# STM32H573 register map
File version: 1.8
CPU: CM33 r0p0, little endian, MPU, FPU, 4 interrupt priority bits
Registers are 32-bit, read-write, reset 0x0 unless marked. A register's access mark holds for its fields unless they carry their own. Offsets are from the block's base; [hi:lo] are bit positions; 'fields as' and 'values as' point back to an identical list.

## RCC (part 1 of 2) — Reset and clock controller
Base 0x44020C00
Same registers: SEC_RCC 0x54020C00
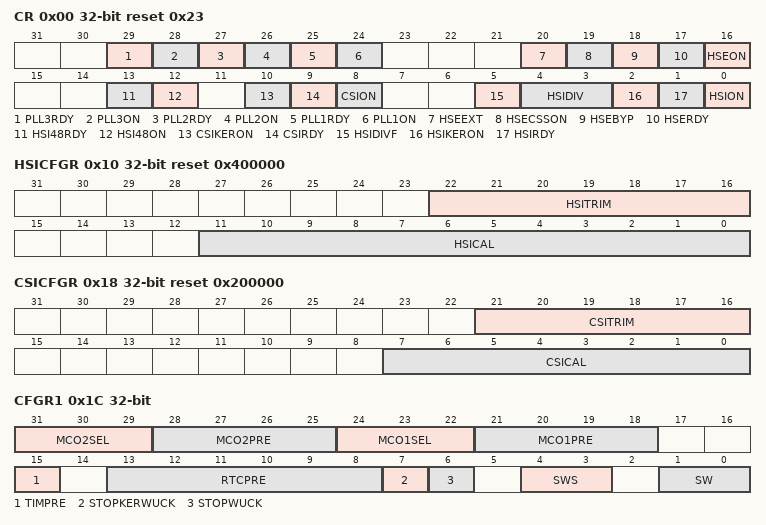
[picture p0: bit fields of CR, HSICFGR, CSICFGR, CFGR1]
0x00 CR access per field reset 0x23 — RCC clock control register
  [29] PLL3RDY ro — PLL3 clock ready flag Set by hardware to indicate that the PLL3 is locked.
    0=NotReady (Clock not ready); 1=Ready (Clock ready)
  [28] PLL3ON rw — PLL3 enable Set and cleared by software to enable PLL3. Cleared by hardware when entering Stop or Standby mode.
    0=Off (Clock Off); 1=On (Clock On)
  [27] PLL2RDY ro — PLL2 clock ready flag Set by hardware to indicate that the PLL is locked.
    0=NotReady (Clock not ready); 1=Ready (Clock ready)
  [26] PLL2ON rw — PLL2 enable Set and cleared by software to enable PLL2. Cleared by hardware when entering Stop or Standby mode.
    0=Off (Clock Off); 1=On (Clock On)
  [25] PLL1RDY ro — PLL1 clock ready flag Set by hardware to indicate that the PLL1 is locked.
    0=NotReady (Clock not ready); 1=Ready (Clock ready)
  [24] PLL1ON rw — PLL1 enable Set and cleared by software to enable PLL1. Cleared by hardware when entering Stop or Standby mode. Note that the hardware prevents writing this bit to 0, if the PLL1 output is used as the system clock.
    0=Off (Clock Off); 1=On (Clock On)
  [20] HSEEXT rw — external high speed clock type in Bypass mode Set and reset by software to select the external clock type (analog or digital). The external clock must be enabled with the HSEON bit to be used by the device. The HSEEXT bit can be written only if the HSE oscillator is disabled.
    0=Analog (HSE in analog mode); 1=Digital (HSE in digital mode)
  [19] HSECSSON rw — HSE clock security system enable Set by software to enable clock security system on HSE. This bit is 'set only' (disabled by a system reset or when the system enters in Standby mode). When HSECSSON is set, the clock detector is enabled by hardware when the HSE is ready and disabled by hardware if an oscillator failure is detected.
    0=Off (Clock Off); 1=On (Clock On)
  [18] HSEBYP rw — HSE clock bypass Set and cleared by software to bypass the oscillator with an external clock. The external clock must be enabled with the HSEON bit to be used by the device. The HSEBYP bit can be written only if the HSE oscillator is disabled.
    0=NotBypassed (HSE crystal oscillator not bypassed); 1=Bypassed (HSE crystal oscillator bypassed with external clock)
  [17] HSERDY ro — HSE clock ready flag Set by hardware to indicate that the HSE oscillator is stable.
    0=NotReady (Clock not ready); 1=Ready (Clock ready)
  [16] HSEON rw — HSE clock enable Set and cleared by software. Cleared by hardware to stop the HSE when entering Stop or Standby mode. This bit cannot be cleared if the HSE is used directly (via SW mux) as system clock, or if the HSE is selected as reference clock for PLL1 with PLL1 enabled (PLL1ON bit set to 1).
    0=Off (Clock Off); 1=On (Clock On)
  [13] HSI48RDY ro — HSI48 clock ready flag Set by hardware to indicate that the HSI48 oscillator is stable.
    0=NotReady (Clock not ready); 1=Ready (Clock ready)
  [12] HSI48ON rw — HSI48 clock enable Set by software and cleared by software or by the hardware when the system enters to Stop or Standby mode.
    0=Off (Clock Off); 1=On (Clock On)
  [10] CSIKERON rw — CSI clock enable in Stop mode Set and reset by software to force the CSI to ON, even in Stop mode, in order to be quickly available as kernel clock for some peripherals. This bit has no effect on the value of CSION.
    0=Off (Clock Off); 1=On (Clock On)
  [9] CSIRDY ro — CSI clock ready flag Set by hardware to indicate that the CSI oscillator is stable. This bit is activated only if the RC is enabled by CSION (it is not activated if the CSI is enabled by CSIKERON or by a peripheral request).
    0=NotReady (Clock not ready); 1=Ready (Clock ready)
  [8] CSION rw — CSI clock enable Set and reset by software to enable/disable CSI clock for system and/or peripheral. Set by hardware to force the CSI to ON when the system leaves Stop mode, if STOPWUCK = 1 or STOPKERWUCK = 1. This bit cannot be cleared if the CSI is used directly (via SW mux) as system clock, or if the CSI is selected as reference clock for PLL1 with PLL1 enabled (PLL1ON bit set to 1).
    0=Off (Clock Off); 1=On (Clock On)
  [5] HSIDIVF ro — HSI divider flag Set and reset by hardware. As a write operation to HSIDIV has not an immediate effect on the frequency, this flag indicates the current status of the HSI divider. HSIDIVF goes immediately to 0 when HSIDIV value is changed, and is set back to 1 when the output frequency matches the value programmed into HSIDIV.
    0=NotPropagated (New HSIDIV ratio has not yet propagated to hsi_ck); 1=Propagated (HSIDIV ratio has propagated to hsi_ck)
  [4:3] HSIDIV rw — HSI clock divider Set and reset by software. These bits allow selecting a division ratio in order to configure the wanted HSI clock frequency. The HSIDIV cannot be changed if the HSI is selected as reference clock for at least one enabled PLL (PLLxON bit set to 1). In that case, the new HSIDIV value is ignored.
    0=Div1 (No division); 1=Div2 (Division by 2); 2=Div4 (Division by 4); 3=Div8 (Division by 8)
  [2] HSIKERON rw — HSI clock enable in Stop mode Set and reset by software to force the HSI to ON, even in Stop mode, in order to be quickly available as kernel clock for peripherals. This bit has no effect on the value of HSION.
    0=Off (Clock Off); 1=On (Clock On)
  [1] HSIRDY ro — HSI clock ready flag Set by hardware to indicate that the HSI oscillator is stable.
    0=NotReady (Clock not ready); 1=Ready (Clock ready)
  [0] HSION rw — HSI clock enable Set and cleared by software. Set by hardware to force the HSI to ON when the product leaves Stop mode, if STOPWUCK = 1 or STOPKERWUCK = 1. Set by hardware to force the HSI to ON when the product leaves Standby mode or in case of a failure of the HSE which is used as the system clock source. This bit cannot be cleared if the HSI is used directly (via SW mux) as system clock, or if the HSI is selected as reference clock for PLL1 with PLL1 enabled (PLL1ON bit set to 1).
    0=Off (Clock Off); 1=On (Clock On)
0x10 HSICFGR access per field reset 0x400000 (reset mask 0xFFFFF000) — RCC HSI calibration register
  [22:16] HSITRIM rw — HSI clock trimming Set by software to adjust calibration. HSITRIM field is added to the engineering option bytes loaded during reset phase (FLASH_HSI_OPT) in order to form the calibration trimming value. HSICAL = HSITRIM + FLASH_HSI_OPT. After a change of HSITRIM it takes one system clock cycle before the new HSITRIM value is updated Note: The reset value of the field is 0x40.
  [11:0] HSICAL ro — HSI clock calibration Set by hardware by option byte loading during system reset nreset. Adjusted by software through trimming bits HSITRIM. This field represents the sum of engineering option byte calibration value and HSITRIM bits value.
0x14 CRRCR ro (reset mask 0xFFFFF000) — RCC clock recovery RC register
  [9:0] HSI48CAL — Internal RC 48 MHz clock calibration Set by hardware by option-byte loading during system reset NRESET. Read-only.
0x18 CSICFGR reset 0x200000 (reset mask 0xFFFFF000) — RCC CSI calibration register
  [21:16] CSITRIM — CSI clock trimming Set by software to adjust calibration. CSITRIM field is added to the engineering option bytes loaded during reset phase (FLASH_CSI_OPT) in order to form the calibration trimming value. CSICAL = CSITRIM + FLASH_CSI_OPT. Note: The reset value of the field is 0x20.
  [7:0] CSICAL — CSI clock calibration Set by hardware by option byte loading during system reset NRESET. Adjusted by software through trimming bits CSITRIM. This field represents the sum of engineering option byte calibration value and CSITRIM bits value.
0x1C CFGR1 access per field — RCC clock configuration register
  [31:29] MCO2SEL rw — microcontroller clock output 2 Set and cleared by software. Clock source selection may generate glitches on MCO2. It is highly recommended to configure these bits only after reset, before enabling the external oscillators and the PLLs. others: reserved
    0=SYSCLK (System clock selected (sys_ck)); 1=PLL2_P (PLL2 oscillator clock selected (pll2_p_ck)); 2=HSE (HSE clock selected (hse_ck)); 3=PLL1_P (PLL1 clock selected (pll1_p_ck)); 4=CSI (CSI clock selected (csi_ck)); 5=LSI (LSI clock selected (lsi_ck))
  [28:25] MCO2PRE rw — MCO2 prescaler Set and cleared by software to configure the prescaler of the MCO2. Modification of this prescaler may generate glitches on MCO2. It is highly recommended to change this prescaler only after reset, before enabling the external oscillators and the PLLs. ...
  [24:22] MCO1SEL rw — Microcontroller clock output 1 Set and cleared by software. Clock source selection may generate glitches on MCO1. It is highly recommended to configure these bits only after reset, before enabling the external oscillators and the PLLs. others: reserved
    0=HSI (HSI clock selected (hsi_ck)); 1=LSE (LSE clock selected (lse_ck)); 2=HSE (HSE clock selected (hse_ck)); 3=PLL1_Q (PLL1 clock selected (pll1_q_ck)); 4=HSI48 (HSI48 clock selected (hsi48_ck))
  [21:18] MCO1PRE rw — MCO1 prescaler Set and cleared by software to configure the prescaler of the MCO1. Modification of this prescaler may generate glitches on MCO1. It is highly recommended to change this prescaler only after reset, before enabling the external oscillators and the PLLs. ...
  [15] TIMPRE rw — timers clocks prescaler selection This bit is set and reset by software to control the clock frequency of all the timers connected to APB1 and APB2 domains.
    0=DefaultX2 (Timer kernel clock equal to 2x pclk by default); 1=DefaultX4 (Timer kernel clock equal to 4x pclk by default)
  [13:8] RTCPRE rw — HSE division factor for RTC clock Set and cleared by software to divide the HSE to generate a clock for RTC. Caution: The software must set these bits correctly to ensure that the clock supplied to the RTC is lower than 1 MHz. These bits must be configured if needed before selecting the RTC clock source. ...
  [7] STOPKERWUCK rw — kernel clock selection after a wakeup from system Stop Set and reset by software to select the kernel wakeup clock from system Stop.
    0=HSI (HSI selected as wake up clock from system Stop); 1=CSI (CSI selected as wake up clock from system Stop)
  [6] STOPWUCK rw — system clock selection after a wakeup from system Stop Set and reset by software to select the system wakeup clock from system Stop. The selected clock is also used as emergency clock for the clock security system (CSS) on HSE. 0: HSI selected as wakeup clock from system Stop (default after reset) STOPWUCK must not be modified when CSS is enabled (by HSECSSON bit) and the system clock is HSE (SWS = 10) or a switch on HSE is requested (SW =10).
    values as STOPKERWUCK
  [4:3] SWS ro — system clock switch status Set and reset by hardware to indicate which clock source is used as system clock. 000: HSI used as system clock (hsi_ck) (default after reset). others: reserved
    0=HSI (HSI oscillator used as system clock); 1=CSI (CSI oscillator used as system clock); 2=HSE (HSE oscillator used as system clock); 3=PLL1 (PLL1 used as system clock)
  [1:0] SW rw — system clock and trace clock switch Set and reset by software to select system clock and trace clock sources (sys_ck). Set by hardware in order to: - force the selection of the HSI or CSI (depending on STOPWUCK selection) when leaving a system Stop mode - force the selection of the HSI in case of failure of the HSE when used directly or indirectly as system clock others: reserved
    0=HSI (HSI selected as system clock); 1=CSI (CSI selected as system clock); 2=HSE (HSE selected as system clock); 3=PLL1 (PLL1 selected as system clock)
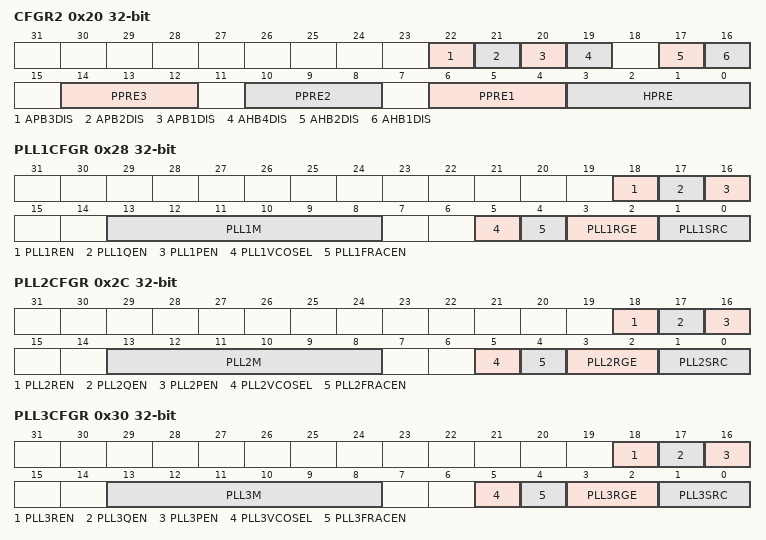
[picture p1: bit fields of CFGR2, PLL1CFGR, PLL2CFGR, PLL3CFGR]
0x20 CFGR2 — RCC CPU domain clock configuration register 2
  [22] APB3DIS — APB3 clock disable value.Set and cleared by software This bit can be set in order to further reduce power consumption, when none of the APB3 peripherals are used and when their clocks are disabled in RCC_APB3ENR. When this bit is set, all the APB3 peripherals clocks are off. control bits
    0=Enabled (The selected clock is enabled); 1=Disabled (The selected clock is disabled)
  [21] APB2DIS — APB2 clock disable value This bit can be set in order to further reduce power consumption, when none of the APB2 peripherals are used and when their clocks are disabled in RCC_APB2ENR. When this bit is set, all the APB2 peripherals clocks are off. control bits
    values as APB3DIS
  [20] APB1DIS — APB1 clock disable value This bit can be set in order to further reduce power consumption, when none of the APB1 peripherals (except IWDG) are used and when their clocks are disabled in RCC_APB1ENR. When this bit is set, all the APB1 peripherals clocks are off, except for IWDG. control bits
    values as APB3DIS
  [19] AHB4DIS — AHB4 clock disable This bit can be set in order to further reduce power consumption, when none of the AHB4 peripherals from RCC_AHB4ENR are used and when their clocks are disabled in RCC_AHB4ENR. When this bit is set, all the AHB4 peripherals clocks from RCC_AHB4ENR are off. enable control bits
    values as APB3DIS
  [17] AHB2DIS — AHB2 clock disable This bit can be set in order to further reduce power consumption, when none of the AHB2 peripherals from RCC_AHB2ENR are used and when their clocks are disabled in RCC_AHB2ENR. When this bit is set, all the AHB2 peripherals clocks from RCC_AHB2ENR are off. enable control bits
    values as APB3DIS
  [16] AHB1DIS — AHB1 clock disable This bit can be set in order to further reduce power consumption, when none of the AHB1 peripherals from RCC_AHB1ENR are used and when their clocks are disabled in RCC_AHB1ENR. When this bit is set, all the AHB1 peripherals clocks from RCC_AHB1ENR are off. enable control bits
    values as APB3DIS
  [14:12] PPRE3 — APB low-speed prescaler (APB3) Set and reset by software to control APB low-speed clocks division factor. The clocks are divided with the new prescaler factor from 1 to 16 APB cycles after PPRE3 write. 0xx: rcc_pclk3 = rcc_hclk1
    4=Div2 (HCLK divided by 2); 5=Div4 (HCLK divided by 4); 6=Div8 (HCLK divided by 8); 7=Div16 (HCLK divided by 16); other=Div1 (HCLK not divided)
  [10:8] PPRE2 — APB high-speed prescaler (APB2) Set and reset by software to control APB high-speed clocks division factor. The clocks are divided with the new prescaler factor from 1 to 16 APB cycles after PPRE2 write. 0xx: rcc_pclk2 = rcc_hclk1
    values as PPRE3
  [6:4] PPRE1 — APB low-speed prescaler (APB1) Set and reset by software to control the division factor of rcc_pclk1. The clock is divided by the new prescaler factor from 1 to 16 cycles of rcc_hclk after PPRE write. 0xx: rcc_pclk1 = rcc_hclk1 (default after reset)
    values as PPRE3
  [3:0] HPRE — AHB prescaler Set and reset by software to control the division factor of rcc_hclk. Changing this division ratio has an impact on the frequency of all bus matrix clocks 0xxx: rcc_hclk = sys_ck (default after reset)
    8=Div2 (SYSCLK divided by 2); 9=Div4 (SYSCLK divided by 4); 10=Div8 (SYSCLK divided by 8); 11=Div16 (SYSCLK divided by 16); 12=Div64 (SYSCLK divided by 64); 13=Div128 (SYSCLK divided by 128); 14=Div256 (SYSCLK divided by 256); 15=Div512 (SYSCLK divided by 512); other=Div1 (SYSCLK not divided)
0x28 PLL1CFGR — RCC PLL clock source selection register
  [18] PLL1REN — PLL1 DIVR divider output enable Set and reset by software to enable the pll1_r_ck output of the PLL1. To save power, DIVR1EN and DIVR1 bits must be set to 0 when the pll1_r_ck is not used. This bit can be written only when the PLL1 is disabled (PLL1ON = 0 and PLL1RDY = 0).
    0=Disabled (Clock output is disabled); 1=Enabled (Clock output is enabled)
  [17] PLL1QEN — PLL1 DIVQ divider output enable Set and reset by software to enable the pll1_q_ck output of the PLL1. In order to save power, when the pll1_q_ck output of the PLL1 is not used, the pll1_q_ck must be disabled. This bit can be written only when the PLL1 is disabled (PLL1ON = 0 and PLL1RDY = 0).
    values as PLL1REN
  [16] PLL1PEN — PLL1 DIVP divider output enable Set and reset by software to enable the pll1_p_ck output of the PLL1. This bit can be written only when the PLL1 is disabled (PLL1ON = 0 and PLL1RDY = 0). In order to save power, when the pll1_p_ck output of the PLL1 is not used, the pll1_p_ck must be disabled.
    values as PLL1REN
  [13:8] PLL1M — prescaler for PLL1 Set and cleared by software to configure the prescaler of the PLL1. The hardware does not allow any modification of this prescaler when PLL1 is enabled (PLL1ON = 1 or PLL1RDY = 1). In order to save power when PLL1 is not used, the value of DIVM1 must be set to 0. ... ...
  [5] PLL1VCOSEL — PLL1 VCO selection Set and reset by software to select the proper VCO frequency range used for PLL1. This bit must be written before enabling the PLL1.
    0=WideVCO (VCO frequency range 192 to 836 MHz); 1=MediumVCO (VCO frequency range 150 to 420 MHz)
  [4] PLL1FRACEN — PLL1 fractional latch enable Set and reset by software to latch the content of FRACN1 into the sigma-delta modulator. In order to latch the FRACN1 value into the sigma-delta modulator, PLL1FRACEN must be set to 0, then set to 1. The transition 0 to 1 transfers the content of FRACN1 into the modulator.
    0=Reset latch to transfer FRACN to the Sigma-Delta modulator; 1=Set (Set latch to transfer FRACN to the Sigma-Delta modulator)
  [3:2] PLL1RGE — PLL1 input frequency range Set and reset by software to select the proper reference frequency range used for PLL1. This bit must be written before enabling the PLL1.
    0=Range1 (Frequency is between 1 and 2 MHz); 1=Range2 (Frequency is between 2 and 4 MHz); 2=Range4 (Frequency is between 4 and 8 MHz); 3=Range8 (Frequency is between 8 and 16 MHz)
  [1:0] PLL1SRC — DIVMx and PLLs clock source selection Set and reset by software to select the PLL clock source. These bits can be written only when all PLLs are disabled. In order to save power, when no PLL is used, the value of PLL1SRC must be set to '00'. 00: no clock send to DIVMx divider and PLLs (default after reset).
    0=None (No clock sent to DIVMx dividers and PLLs); 1=HSI (HSI selected as PLL clock); 2=CSI (CSI selected as PLL clock); 3=HSE (HSE selected as PLL clock)
0x2C PLL2CFGR — RCC PLL clock source selection register
  [18] PLL2REN — PLL2 DIVR divider output enable Set and reset by software to enable the pll2_r_ck output of the PLL2. To save power, DIVR2EN and DIVR2 bits must be set to 0 when the pll2_r_ck is not used.
    values as PLL1CFGR.PLL1REN
  [17] PLL2QEN — PLL2 DIVQ divider output enable Set and reset by software to enable the pll2_q_ck output of the PLL2. To save power, when the pll2_q_ck output of the PLL2 is not used, the pll2_q_ck must be disabled.
    values as PLL1CFGR.PLL1REN
  [16] PLL2PEN — PLL2 DIVP divider output enable Set and reset by software to enable the pll2_p_ck output of the PLL2. To save power, when the pll2_p_ck output of the PLL2 is not used, the pll2_p_ck must be disabled.
    values as PLL1CFGR.PLL1REN
  [13:8] PLL2M — prescaler for PLL2 Set and cleared by software to configure the prescaler of the PLL2. The hardware does not allow any modification of this prescaler when PLL2 is enabled (PLL2ON = 1 or PLL2RDY = 1). In order to save power when PLL2 is not used, the value of DIVM2 must be set to 0. ... ...
  [5] PLL2VCOSEL — PLL2 VCO selection Set and reset by software to select the proper VCO frequency range used for PLL2. This bit must be written before enabling the PLL2.
    values as PLL1CFGR.PLL1VCOSEL
  [4] PLL2FRACEN — PLL2 fractional latch enable Set and reset by software to enable the pll2_p_ck output of the PLL2. To save power, when the pll2_p_ck output of the PLL2 is not used, the pll2_p_ck must be disabled.
    values as PLL1CFGR.PLL1FRACEN
  [3:2] PLL2RGE — PLL2 input frequency range Set and reset by software to select the proper reference frequency range used for PLL2. These bits must be written before enabling the PLL2.
    values as PLL1CFGR.PLL1RGE
  [1:0] PLL2SRC — DIVMx and PLLs clock source selection Set and reset by software to select the PLL clock source. These bits can be written only when all PLLs are disabled. In order to save power, when no PLL is used, the value of PLL2SRC must be set to '00'.
    values as PLL1CFGR.PLL1SRC
0x30 PLL3CFGR — RCC PLL clock source selection register
  [18] PLL3REN — PLL3 DIVR divider output enable Set and reset by software to enable the pll3_r_ck output of the PLL3. To save power, DIVR2EN and DIVR2 bits must be set to 0 when the pll3_r_ck is not used.
    values as PLL1CFGR.PLL1REN
  [17] PLL3QEN — PLL3 DIVQ divider output enable Set and reset by software to enable the pll3_q_ck output of the PLL3. To save power, when the pll3_q_ck output of the PLL3 is not used, the pll3_q_ck must be disabled.
    values as PLL1CFGR.PLL1REN
  [16] PLL3PEN — PLL3 DIVP divider output enable Set and reset by software to enable the pll3_p_ck output of the PLL3. To save power, when the pll3_p_ck output of the PLL3 is not used, the pll3_p_ck must be disabled.
    values as PLL1CFGR.PLL1REN
  [13:8] PLL3M — prescaler for PLL3 Set and cleared by software to configure the prescaler of the PLL3. The hardware does not allow any modification of this prescaler when PLL3 is enabled (PLL3ON = 1 or PLL3RDY = 1). In order to save power when PLL3 is not used, the value of DIVM2 must be set to 0. ... ...
  [5] PLL3VCOSEL — PLL3 VCO selection Set and reset by software to select the proper VCO frequency range used for PLL3. This bit must be written before enabling the PLL3.
    values as PLL1CFGR.PLL1VCOSEL
  [4] PLL3FRACEN — PLL3 fractional latch enable Set and reset by software to latch the content of FRACN3 into the sigma-delta modulator. In order to latch the FRACN3 value into the sigma-delta modulator, PLL3FRACEN must be set to 0, then set to 1. The transition 0 to 1 transfers the content of FRACN3 into the modulator.
    values as PLL1CFGR.PLL1FRACEN
  [3:2] PLL3RGE — PLL3 input frequency range Set and reset by software to select the proper reference frequency range used for PLL3. This bit must be written before enabling the PLL3.
    values as PLL1CFGR.PLL1RGE
  [1:0] PLL3SRC — DIVMx and PLLs clock source selection Set and reset by software to select the PLL clock source. These bits can be written only when all PLLs are disabled. In order to save power, when no PLL is used, the value of PLL3SRC must be set to '00'.
    values as PLL1CFGR.PLL1SRC
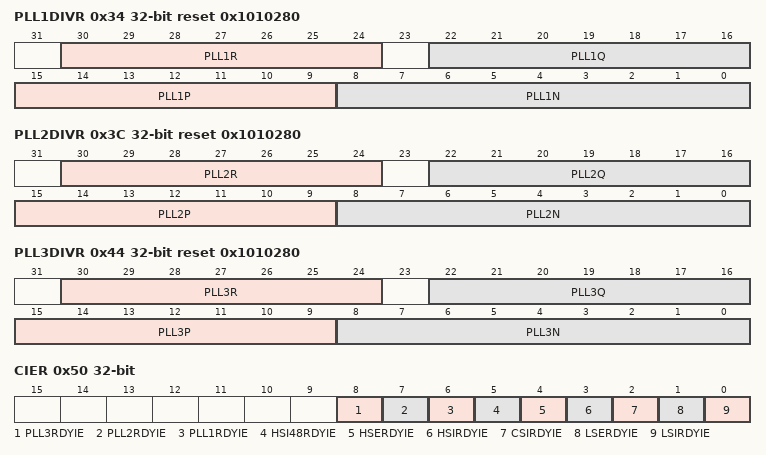
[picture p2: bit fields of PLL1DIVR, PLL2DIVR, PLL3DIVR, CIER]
0x34 PLL1DIVR reset 0x1010280 — RCC PLL1 dividers register
  [30:24] PLL1R — PLL1 DIVR division factor Set and reset by software to control the frequency of the pll1_r_ck clock. These bits can be written only when the PLL1 is disabled (PLL1ON = 0 and PLL1RDY = 0). ...
  [22:16] PLL1Q — PLL1 DIVQ division factor Set and reset by software to control the frequency of the pll1_q_ck clock. These bits can be written only when the PLL1 is disabled (PLL1ON = 0 and PLL1RDY = 0). ...
  [15:9] PLL1P — PLL1 DIVP division factor Set and reset by software to control the frequency of the pll1_p_ck clock. These bits can be written only when the PLL1 is disabled (PLL1ON = 0 and PLL1RDY = 0). Note that odd division factors are not allowed. ...
  [8:0] PLL1N range 3..511 — Multiplication factor for PLL1VCO Set and reset by software to control the multiplication factor of the VCO. These bits can be written only when the PLL is disabled (PLL1ON = 0 and PLL1RDY = 0). ... ... Others: reserved
0x38 PLL1FRACR — RCC PLL1 fractional divider register
  [15:3] PLL1FRACN — fractional part of the multiplication factor for PLL1 VCO Set and reset by software to control the fractional part of the multiplication factor of the VCO. These bits can be written at any time, allowing dynamic fine-tuning of the PLL1 VCO. The software must set correctly these bits to insure that the VCO output frequency is between its valid frequency range, that is: * 128 to 560 MHz if PLL1VCOSEL = 0 * 150 to 420 MHz if PLL1VCOSEL = 1 VCO output frequency = Fref1_ck x (PLL1N + (PLL1FRACN / 213)), with * PLL1N between 8 and 420 * PLL1FRACN can be between 0 and 213- 1 * The input frequency Fref1_ck must be between 1 and 16 MHz. To change the PLL1FRACN value on-the-fly even if the PLL is enabled, the application must proceed as follows: * Set the bit PLL1FRACEN to 0 * Write the new fractional value into PLL1FRACN * Set the bit PLL1FRACEN to 1
0x3C PLL2DIVR reset 0x1010280 — RCC PLL1 dividers register
  [30:24] PLL2R — PLL2 DIVR division factor Set and reset by software to control the frequency of the pll2_r_ck clock. These bits can be written only when the PLL1 is disabled (PLL2ON = 0 and PLL2RDY = 0). ...
  [22:16] PLL2Q — PLL2 DIVQ division factor Set and reset by software to control the frequency of the pll2_q_ck clock. These bits can be written only when the PLL2 is disabled (PLL2ON = 0 and PLL2RDY = 0). ...
  [15:9] PLL2P — PLL2 DIVP division factor Set and reset by software to control the frequency of the pll2_p_ck clock. These bits can be written only when the PLL2 is disabled (PLL2ON = 0 and PLL2RDY = 0). ...
  [8:0] PLL2N range 3..511 — Multiplication factor for PLL2VCO Set and reset by software to control the multiplication factor of the VCO. These bits can be written only when the PLL is disabled (PLL2ON = 0 and PLL2RDY = 0). ... ... Others: reserved
0x40 PLL2FRACR — RCC PLL2 fractional divider register
  [15:3] PLL2FRACN — fractional part of the multiplication factor for PLL2 VCO Set and reset by software to control the fractional part of the multiplication factor of the VCO. These bits can be written at any time, allowing dynamic fine-tuning of the PLL2 VCO. The software must set correctly these bits to insure that the VCO output frequency is between its valid frequency range, that is: * 128 to 560 MHz if PLL2VCOSEL = 0 * 150 to 420 MHz if PLL2VCOSEL = 1 VCO output frequency = Fref2_ck x (PLL2N + (PLL2FRACN / 213)), with * PLL2N between 8 and 420 * PLL2FRACN can be between 0 and 213- 1 * The input frequency Fref2_ck must be between 1 and 16 MHz. To change the PLL2FRACN value on-the-fly even if the PLL is enabled, the application must proceed as follows: * Set the bit PLL2FRACEN to 0 * Write the new fractional value into PLL2FRACN * Set the bit PLL2FRACEN to 1
0x44 PLL3DIVR reset 0x1010280 — RCC PLL3 dividers register
  [30:24] PLL3R — PLL3 DIVR division factor Set and reset by software to control the frequency of the pll3_r_ck clock. These bits can be written only when the PLL1 is disabled (PLL3ON = 0 and PLL3RDY = 0). ...
  [22:16] PLL3Q — PLL3 DIVQ division factor Set and reset by software to control the frequency of the pll3_q_ck clock. These bits can be written only when the PLL3 is disabled (PLL3ON = 0 and PLL3RDY = 0). ...
  [15:9] PLL3P — PLL3 DIVP division factor Set and reset by software to control the frequency of the pll3_p_ck clock. These bits can be written only when the PLL3 is disabled (PLL3ON = 0 and PLL3RDY = 0). ...
  [8:0] PLL3N range 3..511 — Multiplication factor for PLL3VCO Set and reset by software to control the multiplication factor of the VCO. These bits can be written only when the PLL is disabled (PLL3ON = 0 and PLL3RDY = 0). ... ... Others: reserved
0x48 PLL3FRACR — RCC PLL3 fractional divider register
  [15:3] PLL3FRACN — fractional part of the multiplication factor for PLL3 VCO Set and reset by software to control the fractional part of the multiplication factor of the VCO. These bits can be written at any time, allowing dynamic fine-tuning of the PLL3 VCO. The software must set correctly these bits to insure that the VCO output frequency is between its valid frequency range, that is: * 128 to 560 MHz if PLL3VCOSEL = 0 * 150 to 420 MHz if PLL3VCOSEL = 1 VCO output frequency = Fref3_ck x (PLL3N + (PLL3FRACN / 213)), with * PLL3N between 8 and 420 * PLL3FRACN can be between 0 and 213- 1 * The input frequency Fref3_ck must be between 1 and 16 MHz. To change the PLL3FRACN value on-the-fly even if the PLL is enabled, the application must proceed as follows: * Set the bit PLL3FRACEN to 0 * Write the new fractional value into PLL3FRACN * Set the bit PLL3FRACEN to 1.
0x50 CIER — RCC clock source interrupt enable register
  [all] fields
    0=Disabled (Interrupt disabled); 1=Enabled (Interrupt enabled)
  [8] PLL3RDYIE — PLL3 ready interrupt enable Set and reset by software to enable/disable interrupt caused by PLL3 lock.
  [7] PLL2RDYIE — PLL2 ready interrupt enable Set and reset by software to enable/disable interrupt caused by PLL2 lock.
  [6] PLL1RDYIE — PLL1 ready interrupt enable Set and reset by software to enable/disable interrupt caused by PLL1 lock.
  [5] HSI48RDYIE — HSI48 ready interrupt enable Set and reset by software to enable/disable interrupt caused by the HSI48 oscillator stabilization.
  [4] HSERDYIE — HSE ready interrupt enable Set and reset by software to enable/disable interrupt caused by the HSE oscillator stabilization.
  [3] HSIRDYIE — HSI ready interrupt enable Set and reset by software to enable/disable interrupt caused by the HSI oscillator stabilization.
  [2] CSIRDYIE — CSI ready interrupt enable Set and reset by software to enable/disable interrupt caused by the CSI oscillator stabilization.
  [1] LSERDYIE — LSE ready interrupt enable Set and reset by software to enable/disable interrupt caused by the LSE oscillator stabilization.
  [0] LSIRDYIE — LSI ready interrupt enable Set and reset by software to enable/disable interrupt caused by the LSI oscillator stabilization.
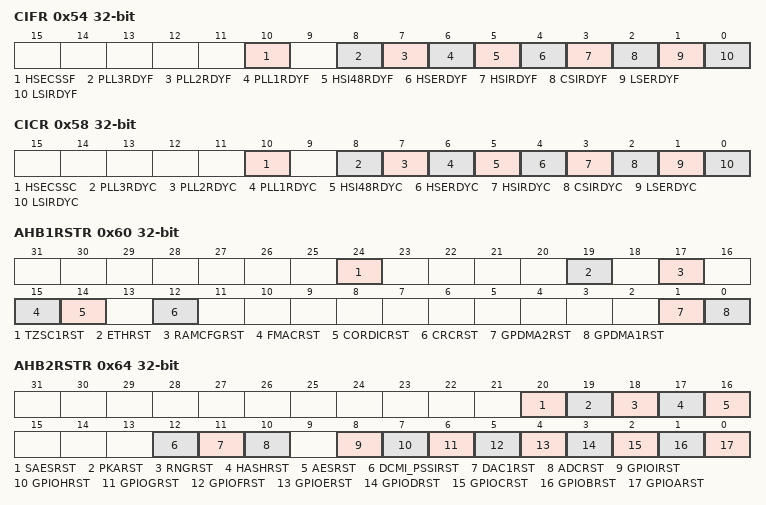
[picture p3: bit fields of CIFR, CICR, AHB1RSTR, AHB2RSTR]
0x54 CIFR ro — RCC clock source interrupt flag register
  [10] HSECSSF — HSE clock security system interrupt flag Reset by software by writing HSECSSC bit. Set by hardware in case of HSE clock failure.
    0=NoInterrupt (No clock security interrupt caused by HSE clock failure); 1=Interrupt (Clock security interrupt caused by HSE clock failure)
  [8] PLL3RDYF — PLL3 ready interrupt flag Reset by software by writing PLL3RDYC bit. Set by hardware when the PLL3 locks and PLL3RDYIE is set.
    0=NotInterrupted (No clock ready interrupt); 1=Interrupted (Clock ready interrupt)
  [7] PLL2RDYF — PLL2 ready interrupt flag Reset by software by writing PLL2RDYC bit. Set by hardware when the PLL2 locks and PLL2RDYIE is set.
    values as PLL3RDYF
  [6] PLL1RDYF — PLL1 ready interrupt flag Reset by software by writing PLL1RDYC bit. Set by hardware when the PLL1 locks and PLL1RDYIE is set.
    values as PLL3RDYF
  [5] HSI48RDYF — HSI48 ready interrupt flag Reset by software by writing HSI48RDYC bit. Set by hardware when the HSI48 clock becomes stable and HSI48RDYIE is set.
    values as PLL3RDYF
  [4] HSERDYF — HSE ready interrupt flag Reset by software by writing HSERDYC bit. Set by hardware when the HSE clock becomes stable and HSERDYIE is set.
    values as PLL3RDYF
  [3] HSIRDYF — HSI ready interrupt flag Reset by software by writing HSIRDYC bit. Set by hardware when the HSI clock becomes stable and HSIRDYIE is set.
    values as PLL3RDYF
  [2] CSIRDYF — CSI ready interrupt flag Reset by software by writing CSIRDYC bit. Set by hardware when the CSI clock becomes stable and CSIRDYIE is set.
    values as PLL3RDYF
  [1] LSERDYF — LSE ready interrupt flag Reset by software by writing LSERDYC bit. Set by hardware when the LSE clock becomes stable and LSERDYIE is set.
    values as PLL3RDYF
  [0] LSIRDYF — LSI ready interrupt flag Reset by software by writing LSIRDYC bit. Set by hardware when the LSI clock becomes stable and LSIRDYIE is set.
    values as PLL3RDYF
0x58 CICR — RCC clock source interrupt clear register
  [all] fields
    1=Clear interrupt flag
  [10] HSECSSC — HSE clock security system interrupt clear Set by software to clear HSECSSF. Reset by hardware when clear done.
  [8] PLL3RDYC — PLL3 ready interrupt clear Set by software to clear PLL3RDYF. Reset by hardware when clear done.
  [7] PLL2RDYC — PLL2 ready interrupt clear Set by software to clear PLL2RDYF. Reset by hardware when clear done.
  [6] PLL1RDYC — PLL1 ready interrupt clear Set by software to clear PLL1RDYF. Reset by hardware when clear done.
  [5] HSI48RDYC — HSI48 ready interrupt clear Set by software to clear HSI48RDYF. Reset by hardware when clear done.
  [4] HSERDYC — HSE ready interrupt clear Set by software to clear HSERDYF. Reset by hardware when clear done.
  [3] HSIRDYC — HSI ready interrupt clear Set by software to clear HSIRDYF. Reset by hardware when clear done.
  [2] CSIRDYC — HSI ready interrupt clear Set by software to clear CSIRDYF. Reset by hardware when clear done.
  [1] LSERDYC — LSE ready interrupt clear Set by software to clear LSERDYF. Reset by hardware when clear done.
  [0] LSIRDYC — LSI ready interrupt clear Set by software to clear LSIRDYF. Reset by hardware when clear done.
0x60 AHB1RSTR — RCC AHB1 reset register
  [all] fields
    1=Reset the selected module
  [24] TZSC1RST — TZSC1 reset Set and reset by software
  [19] ETHRST — ETHRST block reset Set and reset by software
  [17] RAMCFGRST — RAMCFG block reset Set and reset by software.
  [15] FMACRST — FMAC block reset Set and reset by software.
  [14] CORDICRST — CORDIC block reset Set and reset by software.
  [12] CRCRST — CRC block reset Set and reset by software.
  [1] GPDMA2RST — GPDMA2 block reset Set and reset by software.
  [0] GPDMA1RST — GPDMA1 block reset Set and reset by software.
0x64 AHB2RSTR — RCC AHB2 peripheral reset register
  [all] fields
    1=Reset the selected module
  [20] SAESRST — SAES block reset Set and reset by software.
  [19] PKARST — PKA block reset Set and reset by software.
  [18] RNGRST — RNG block reset Set and reset by software.
  [17] HASHRST — HASH block reset Set and reset by software.
  [16] AESRST — AES block reset Set and reset by software.
  [12] DCMI_PSSIRST — digital camera interface block reset (DCMI or PSSI depending which interface is active) Set and reset by software.
  [11] DAC1RST — DAC block reset
  [10] ADCRST — ADC1 and 2 blocks reset
  [8] GPIOIRST — GPIOI block reset Set and reset by software.
  [7] GPIOHRST — GPIOH block reset Set and reset by software.
  [6] GPIOGRST — GPIOG block reset Set and reset by software.
  [5] GPIOFRST — GPIOF block reset Set and reset by software.
  [4] GPIOERST — GPIOE block reset Set and reset by software.
  [3] GPIODRST — GPIOD block reset Set and reset by software.
  [2] GPIOCRST — GPIOC block reset Set and reset by software.
  [1] GPIOBRST — GPIOB block reset Set and reset by software.
  [0] GPIOARST — GPIOA block reset Set and reset by software.
